# STM32MP13xx register map
File version: 1.5
CPU: CA7 r0p0, little endian, MPU, FPU, 4 interrupt priority bits
Registers are 32-bit, read-write, reset 0x0 unless marked. A register's access mark holds for its fields unless they carry their own. Offsets are from the block's base; [hi:lo] are bit positions; lines under a group give offsets from that group; {n}, {i} and the like mark numbered series; 'fields as' and 'values as' point back to an identical list.

## DFSDM
Base 0x4400D000
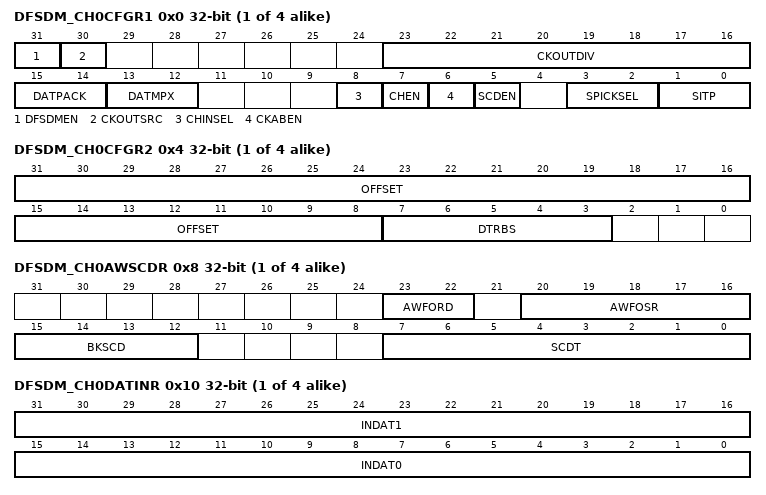
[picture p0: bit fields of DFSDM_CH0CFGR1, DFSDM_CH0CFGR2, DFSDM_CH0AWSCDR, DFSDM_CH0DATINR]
{0x0+0x20*i} DFSDM_CH{i}CFGR1 (i=0..3) — DFSDM channel {i} configuration register
  [31] DFSDMEN — Global enable for DFSDM interface If DFSDM interface is enabled, then it is started to operate according to enabled y channels and enabled x filters settings (CHEN bit in DFSDM_CHyCFGR1 and DFEN bit in DFSDM_FLTxCR1). Data cleared by setting DFSDMEN=0: all registers DFSDM_FLTxISR are set to reset state (x = 0..1) all registers DFSDM_FLTxAWSR are set to reset state (x = 0..1) Note: DFSDMEN is present only in DFSDM_CH0CFGR1 register (channel y=0)
    0=DFSDM interface disabled; 1=DFSDM interface enabled
  [30] CKOUTSRC — Output serial clock source selection This value can be modified only when DFSDMEN=0 (in DFSDM_CH0CFGR1 register). Note: CKOUTSRC is present only in DFSDM_CH0CFGR1 register (channel y=0)
    0=Source for output clock is from system clock; 1=Source for output clock is from audio clock
  [23:16] CKOUTDIV — Output serial clock divider Â 256 (Divider = CKOUTDIV+1). CKOUTDIV also defines the threshold for a clock absence detection. This value can only be modified when DFSDMEN=0 (in DFSDM_CH0CFGR1 register). If DFSDMEN=0 (in DFSDM_CH0CFGR1 register) then CKOUT signal is set to low state (setting is performed one DFSDM clock cycle after DFSDMEN=0). Note: CKOUTDIV is present only in DFSDM_CH0CFGR1 register (channel y=0) 1- 255: Defines the division of system clock for the serial clock output for CKOUT signal in range 2Â -
    0=Output clock generation is disabled (CKOUT signal is set to low state)
  [15:14] DATPACK — Data packing mode in DFSDM_CHyDATINR register. first sample in INDAT0[15:0] (assigned to channel y) second sample INDAT1[15:0] (assigned to channel y) To empty DFSDM_CHyDATINR register, two samples must be read by the digital filter from channel y (INDAT0[15:0] part is read as first sample and then INDAT1[15:0] part is read as next sample). 2: Dual: input data in DFSDM_CHyDATINR register are stored as two samples: first sample INDAT0[15:0] (assigned to channel y) second sample INDAT1[15:0] (assigned to channel y+1) To empty DFSDM_CHyDATINR register first sample must be read by the digital filter from channel y and second sample must be read by another digital filter from channel y+1. Dual mode is available only on even channel numbers (y = 0, 2), for odd channel numbers (y = 1, 3) DFSDM_CHyDATINR is write protected. If an even channel is set to dual mode then the following odd channel must be set into standard mode (DATPACK[1:0]=0) for correct cooperation with even channel. 3: Reserved This value can be modified only when CHEN=0 (in DFSDM_CHyCFGR1 register).
    0=Standard: input data in DFSDM_CHyDATINR register are stored only in INDAT0[15:0]. To empty DFSDM_CHyDATINR register one sample must be read by the DFSDM filter from channel y.; 1=Interleaved: input data in DFSDM_CHyDATINR register are stored as two samples:
  [13:12] DATMPX — Input data multiplexer for channel y 2: Data to channel y are taken from internal DFSDM_CHyDATINR register by direct CPU/DMA write. There can be written one or two 16-bit data samples according DATPACK[1:0] bit field setting. 3: Reserved This value can be modified only when CHEN=0 (in DFSDM_CHyCFGR1 register).
    0=Data to channel y are taken from external serial inputs as 1-bit values. DFSDM_CHyDATINR register is write protected.; 1=Data to channel y are taken from internal analog to digital converter ADCy+1 output register update as 16-bit values (if ADCy+1 is available). Data from ADCs are written into INDAT0[15:0] part of DFSDM_CHyDATINR register.
  [8] CHINSEL — Channel inputs selection This value can be modified only when CHEN=0 (in DFSDM_CHyCFGR1 register).
    0=Channel inputs are taken from pins of the same channel y; 1=Channel inputs are taken from pins of the following channel (channel (y+1) modulo 8)
  [7] CHEN — Channel y enable If channel y is enabled, then serial data receiving is started according to the given channel setting.
    0=Channel y disabled; 1=Channel y enabled
  [6] CKABEN — Clock absence detector enable on channel y
    0=Clock absence detector disabled on channel y; 1=Clock absence detector enabled on channel y
  [5] SCDEN — Short-circuit detector enable on channel y
    0=Input channel y will not be guarded by the short-circuit detector; 1=Input channel y will be continuously guarded by the short-circuit detector
  [3:2] SPICKSEL — SPI clock select for channel y 2: clock coming from internal CKOUT - sampling point on each second CKOUT falling edge. For connection to external Î£â modulator which divides its clock input (from CKOUT) by 2 to generate its output serial communication clock (and this output clock change is active on each clock input rising edge). 3: clock coming from internal CKOUT output - sampling point on each second CKOUT rising edge. For connection to external Î£â modulator which divides its clock input (from CKOUT) by 2 to generate its output serial communication clock (and this output clock change is active on each clock input falling edge). This value can be modified only when CHEN=0 (in DFSDM_CHyCFGR1 register).
    0=clock coming from external CKINy input - sampling point according SITP[1:0]; 1=clock coming from internal CKOUT output - sampling point according SITP[1:0]
  [1:0] SITP — Serial interface type for channel y This value can only be modified when CHEN=0 (in DFSDM_CHyCFGR1 register).
    0=SPI with rising edge to strobe data; 1=SPI with falling edge to strobe data; 2=Manchester coded input on DATINy pin: rising edge = logic 0, falling edge = logic 1; 3=Manchester coded input on DATINy pin: rising edge = logic 1, falling edge = logic 0
{0x4+0x20*i} DFSDM_CH{i}CFGR2 (i=0..3) — DFSDM channel {i} configuration register
  [31:8] OFFSET — 24-bit calibration offset for channel y For channel y, OFFSET is applied to the results of each conversion from this channel. This value is set by software.
  [7:3] DTRBS — Data right bit-shift for channel y will be performed to have final results. Bit-shift is performed before offset correction. The data shift is rounding the result to nearest integer value. The sign of shifted result is maintained (to have valid 24-bit signed format of result data). This value can be modified only when CHEN=0 (in DFSDM_CHyCFGR1 register). 0-31: Defines the shift of the data result coming from the integrator - how many bit shifts to the right
{0x8+0x20*i} DFSDM_CH{i}AWSCDR (i=0..3) — DFSDM channel {i} analog watchdog and short-circuit detector register
  [23:22] AWFORD — Analog watchdog Sinc filter order on channel y 2: Sinc2 filter type 3: Sinc3 filter type Sincx filter type transfer function: FastSinc filter type transfer function: This bit can be modified only when CHEN=0 (in DFSDM_CHyCFGR1 register).
    0=FastSinc filter type; 1=Sinc1 filter type
  [20:16] AWFOSR — Analog watchdog filter oversampling ratio (decimation rate) on channel y also the decimation ratio of the analog data rate. This bit can be modified only when CHEN=0 (in DFSDM_CHyCFGR1 register). Note: If AWFOSR = 0 then the filter has no effect (filter bypass). 0 - 31: Defines the length of the Sinc type filter in the range 1 - 32 (AWFOSR + 1). This number is
  [15:12] BKSCD — Break signal assignment for short-circuit detector on channel y BKSCD[i] = 0: Break i signal not assigned to short-circuit detector on channel y BKSCD[i] = 1: Break i signal assigned to short-circuit detector on channel y
  [7:0] SCDT — short-circuit detector threshold for channel y These bits are written by software to define the threshold counter for the short-circuit detector. If this value is reached, then a short-circuit detector event occurs on a given channel.
{0xC+0x20*i} DFSDM_CH{i}WDATR ro (i=0..3) — DFSDM channel {i} watchdog filter data register
  [15:0] WDATA — Input channel y watchdog data Data converted by the analog watchdog filter for input channel y. This data is continuously converted (no trigger) for this channel, with a limited resolution (OSR=1..32/sinc order = 1..3).
{0x10+0x20*i} DFSDM_CH{i}DATINR (i=0..3) — DFSDM channel {i} data input register
  [31:16] INDAT1 — Input data for channel y or channel y+1 Input parallel channel data to be processed by the digital filter if DATMPX[1:0]=1 or DATMPX[1:0]=2. Data can be written by CPU/DMA (if DATMPX[1:0]=2) or directly by internal ADC (if DATMPX[1:0]=1). If DATPACK[1:0]=0 (standard mode) INDAT0[15:0] is write protected (not used for input sample). If DATPACK[1:0]=1 (interleaved mode) Second channel y data sample is stored into INDAT1[15:0]. First channel y data sample is stored into INDAT0[15:0]. Both samples are read sequentially by DFSDM_FLTx filter as two channel y data samples. If DATPACK[1:0]=2 (dual mode). For even y channels: sample in INDAT1[15:0] is automatically copied into INDAT0[15:0] of channel (y+1). For odd y channels: INDAT1[15:0] is write protected. See for more details. INDAT0[15:1] is in the16-bit signed format.
  [15:0] INDAT0 — Input data for channel y Input parallel channel data to be processed by the digital filter if DATMPX[1:0]=1 or DATMPX[1:0]=2. Data can be written by CPU/DMA (if DATMPX[1:0]=2) or directly by internal ADC (if DATMPX[1:0]=1). If DATPACK[1:0]=0 (standard mode) Channel y data sample is stored into INDAT0[15:0]. If DATPACK[1:0]=1 (interleaved mode) First channel y data sample is stored into INDAT0[15:0]. Second channel y data sample is stored into INDAT1[15:0]. Both samples are read sequentially by DFSDM_FLTx filter as two channel y data samples. If DATPACK[1:0]=2 (dual mode). For even y channels: Channel y data sample is stored into INDAT0[15:0]. For odd y channels: INDAT0[15:0] is write protected. See for more details. INDAT0[15:0] is in the16-bit signed format.
{0x14+0x20*i} DFSDM_CH{i}DLYR (i=0..7)
  [5:0] PLSSKP — Pulses to skip for input data skipping function immediately after writing to this field. Reading of PLSSKP[5:0] returns current value of pulses which will be skipped. If PLSSKP[5:0]=0 then all required data samples were already skipped. Note: User can update PLSSKP[5:0] also when PLSSKP[5:0] is not zero. 0-63: Defines the number of serial input samples that will be skipped. Skipping is applied
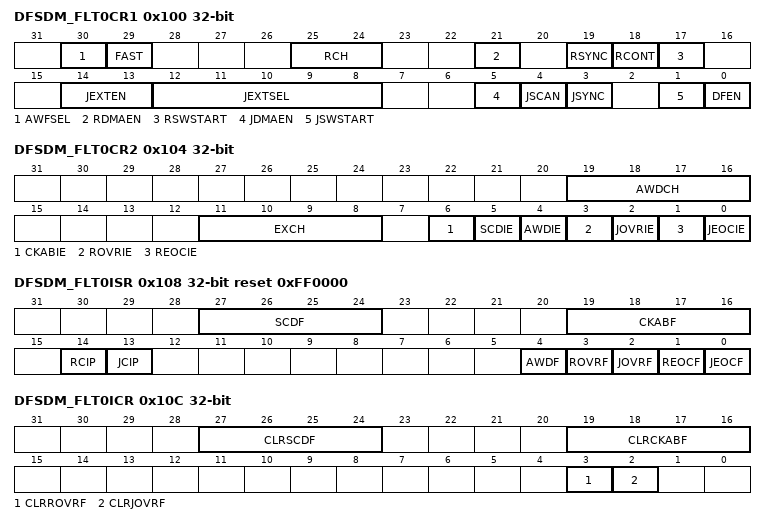
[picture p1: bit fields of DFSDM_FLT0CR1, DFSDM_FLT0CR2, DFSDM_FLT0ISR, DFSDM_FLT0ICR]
0x100 DFSDM_FLT0CR1
  [30] AWFSEL — Analog watchdog fast mode select
    0=Analog watchdog on data output value (after the digital filter). The comparison is done after offset correction and shift; 1=Analog watchdog on channel transceivers value (after watchdog filter)
  [29] FAST — Fast conversion mode selection for regular conversions When converting a regular conversion in continuous mode, having enabled the fast mode causes each conversion (except the first) to execute faster than in standard mode. This bit has no effect on conversions which are not continuous. This bit can be modified only when DFEN=0 (DFSDM_FLTxCR1). if FAST=0 (or first conversion in continuous mode if FAST=1): t = [FOSR * (IOSR-1 + FORD) + FORD] / fCKIN ..... for Sincx filters t = [FOSR * (IOSR-1 + 4) + 2] / fCKIN ..... for FastSinc filter if FAST=1 in continuous mode (except first conversion): t = [FOSR * IOSR] / fCKIN in case if FOSR = FOSR[9:0]+1 = 1 (filter bypassed, active only integrator): t = IOSR / fCKIN (... but CNVCNT=0) where: fCKIN is the channel input clock frequency (on given channel CKINy pin) or input data rate in case of parallel data input.
    0=Fast conversion mode disabled; 1=Fast conversion mode enabled
  [25:24] RCH — Regular channel selection ... 3: Chanel 3 is selected as the regular channel Writing this bit when RCIP=1 takes effect when the next regular conversion begins. This is especially useful in continuous mode (when RCONT=1). It also affects regular conversions which are pending (due to ongoing injected conversion).
    0=Channel 0 is selected as the regular channel; 1=Channel 1 is selected as the regular channel
  [21] RDMAEN — DMA channel enabled to read data for the regular conversion This bit can be modified only when DFEN=0 (DFSDM_FLTxCR1).
    0=The DMA channel is not enabled to read regular data; 1=The DMA channel is enabled to read regular data
  [19] RSYNC — Launch regular conversion synchronously with DFSDM_FLT0 This bit can be modified only when DFEN=0 (DFSDM_FLTxCR1).
    0=Do not launch a regular conversion synchronously with DFSDM_FLT0; 1=Launch a regular conversion in this DFSDM_FLTx at the very moment when a regular conversion is launched in DFSDM_FLT0
  [18] RCONT — Continuous mode selection for regular conversions Writing '0â to this bit while a continuous regular conversion is already in progress stops the continuous mode immediately.
    0=The regular channel is converted just once for each conversion request; 1=The regular channel is converted repeatedly after each conversion request
  [17] RSWSTART — Software start of a conversion on the regular channel This bit is always read as '0â.
    0=Writing '0â has no effect; 1=Writing '1â makes a request to start a conversion on the regular channel and causes RCIP to become '1â. If RCIP=1 already, writing to RSWSTART has no effect. Writing '1â has no effect if RSYNC=1.
  [14:13] JEXTEN — Trigger enable and trigger edge selection for injected conversions This bit can be modified only when DFEN=0 (DFSDM_FLTxCR1).
    0=Trigger detection is disabled; 1=Each rising edge on the selected trigger makes a request to launch an injected conversion; 2=Each falling edge on the selected trigger makes a request to launch an injected conversion; 3=Both rising edges and falling edges on the selected trigger make requests to launch injected conversions
  [12:8] JEXTSEL — Trigger signal selection for launching injected conversions This bit can be modified only when DFEN=0 (DFSDM_FLTxCR1). Note: synchronous trigger has latency up to one fDFSDMCLK clock cycle (with deterministic jitter), asynchronous trigger has latency 2-3 fDFSDMCLK clock cycles (with jitter up to 1 cycle). DFSDM_FLTx 0x00 dfsdm_jtrg0 0x01 dfsdm_jtrg1 ... 0x1E dfsdm_jtrg30 0x1F dfsdm_jtrg31 Refer to . 0x0-0x1F: Trigger inputs selected by the following table (internal or external trigger).
  [5] JDMAEN — DMA channel enabled to read data for the injected channel group This bit can be modified only when DFEN=0 (DFSDM_FLTxCR1).
    0=The DMA channel is not enabled to read injected data; 1=The DMA channel is enabled to read injected data
  [4] JSCAN — Scanning conversion mode for injected conversions This bit can be modified only when DFEN=0 (DFSDM_FLTxCR1). Writing JCHG if JSCAN=0 resets the channel selection to the lowest selected channel.
    0=One channel conversion is performed from the injected channel group and next the selected channel from this group is selected; 1=The series of conversions for the injected group channels is executed, starting over with the lowest selected channel
  [3] JSYNC — Launch an injected conversion synchronously with the DFSDM_FLT0 JSWSTART trigger This bit can be modified only when DFEN=0 (DFSDM_FLTxCR1).
    0=Do not launch an injected conversion synchronously with DFSDM_FLT0; 1=Launch an injected conversion in this DFSDM_FLTx at the very moment when an injected conversion is launched in DFSDM_FLT0 by its JSWSTART trigger
  [1] JSWSTART — Start a conversion of the injected group of channels This bit is always read as '0â.
    0=Writing '0â has no effect; 1=Writing '1â makes a request to convert the channels in the injected conversion group, causing JCIP to become '1â at the same time. If JCIP=1 already, then writing to JSWSTART has no effect. Writing '1â has no effect if JSYNC=1.
  [0] DFEN — DFSDM_FLTx enable Data which are cleared by setting DFEN=0: register DFSDM_FLTxISR is set to the reset state register DFSDM_FLTxAWSR is set to the reset state
    0=DFSDM_FLTx is disabled. All conversions of given DFSDM_FLTx are stopped immediately and all DFSDM_FLTx functions are stopped.; 1=DFSDM_FLTx is enabled. If DFSDM_FLTx is enabled, then DFSDM_FLTx starts operating according to its setting.
0x104 DFSDM_FLT0CR2
  [19:16] AWDCH — Analog watchdog channel selection These bits select the input channel to be guarded continuously by the analog watchdog. AWDCH[y] = 0: Analog watchdog is disabled on channel y AWDCH[y] = 1: Analog watchdog is enabled on channel y
  [11:8] EXCH — Extremes detector channel selection These bits select the input channels to be taken by the Extremes detector. EXCH[y] = 0: Extremes detector does not accept data from channel y EXCH[y] = 1: Extremes detector accepts data from channel y
  [6] CKABIE — Clock absence interrupt enable Please see the explanation of CKABF[3:0] in DFSDM_FLTxISR. Note: CKABIE is present only in DFSDM_FLT0CR2 register (filter x=0)
    0=Detection of channel input clock absence interrupt is disabled; 1=Detection of channel input clock absence interrupt is enabled
  [5] SCDIE — Short-circuit detector interrupt enable Please see the explanation of SCDF[3:0] in DFSDM_FLTxISR. Note: SCDIE is present only in DFSDM_FLT0CR2 register (filter x=0)
    0=short-circuit detector interrupt is disabled; 1=short-circuit detector interrupt is enabled
  [4] AWDIE — Analog watchdog interrupt enable Please see the explanation of AWDF in DFSDM_FLTxISR.
    0=Analog watchdog interrupt is disabled; 1=Analog watchdog interrupt is enabled
  [3] ROVRIE — Regular data overrun interrupt enable Please see the explanation of ROVRF in DFSDM_FLTxISR.
    0=Regular data overrun interrupt is disabled; 1=Regular data overrun interrupt is enabled
  [2] JOVRIE — Injected data overrun interrupt enable Please see the explanation of JOVRF in DFSDM_FLTxISR.
    0=Injected data overrun interrupt is disabled; 1=Injected data overrun interrupt is enabled
  [1] REOCIE — Regular end of conversion interrupt enable Please see the explanation of REOCF in DFSDM_FLTxISR.
    0=Regular end of conversion interrupt is disabled; 1=Regular end of conversion interrupt is enabled
  [0] JEOCIE — Injected end of conversion interrupt enable Please see the explanation of JEOCF in DFSDM_FLTxISR.
    0=Injected end of conversion interrupt is disabled; 1=Injected end of conversion interrupt is enabled
0x108 DFSDM_FLT0ISR ro reset 0xFF0000
  [27:24] SCDF — short-circuit detector flag SDCF[y]=0: No short-circuit detector event occurred on channel y SDCF[y]=1: The short-circuit detector counter reaches, on channel y, the value programmed in the DFSDM_CHyAWSCDR registers This bit is set by hardware. It can be cleared by software using the corresponding CLRSCDF[y] bit in the DFSDM_FLTxICR register. SCDF[y] is cleared also by hardware when CHEN[y] = 0 (given channel is disabled). Note: SCDF[3:0] is present only in DFSDM_FLT0ISR register (filter x=0)
  [19:16] CKABF — Clock absence flag CKABF[y]=0: Clock signal on channel y is present. CKABF[y]=1: Clock signal on channel y is not present. Given y bit is set by hardware when clock absence is detected on channel y. It is held at CKABF[y]=1 state by hardware when CHEN=0 (see DFSDM_CHyCFGR1 register). It is held at CKABF[y]=1 state by hardware when the transceiver is not yet synchronized.It can be cleared by software using the corresponding CLRCKABF[y] bit in the DFSDM_FLTxICR register. Note: CKABF[3:0] is present only in DFSDM_FLT0ISR register (filter x=0)
  [14] RCIP — Regular conversion in progress status A request to start a regular conversion is ignored when RCIP=1.
    0=No request to convert the regular channel has been issued; 1=The conversion of the regular channel is in progress or a request for a regular conversion is pending
  [13] JCIP — Injected conversion in progress status A request to start an injected conversion is ignored when JCIP=1.
    0=No request to convert the injected channel group (neither by software nor by trigger) has been issued; 1=The conversion of the injected channel group is in progress or a request for a injected conversion is pending, due either to '1â being written to JSWSTART or to a trigger detection
  [4] AWDF — Analog watchdog This bit is set by hardware. It is cleared by software by clearing all source flag bits AWHTF[3:0] and AWLTF[3:0] in DFSDM_FLTxAWSR register (by writing '1â into the clear bits in DFSDM_FLTxAWCFR register).
    0=No Analog watchdog event occurred; 1=The analog watchdog block detected voltage which crosses the value programmed in the DFSDM_FLTxAWLTR or DFSDM_FLTxAWHTR registers
  [3] ROVRF — Regular conversion overrun flag This bit is set by hardware. It can be cleared by software using the CLRROVRF bit in the DFSDM_FLTxICR register.
    0=No regular conversion overrun has occurred; 1=A regular conversion overrun has occurred, which means that a regular conversion finished while REOCF was already '1â. RDATAR is not affected by overruns
  [2] JOVRF — Injected conversion overrun flag This bit is set by hardware. It can be cleared by software using the CLRJOVRF bit in the DFSDM_FLTxICR register.
    0=No injected conversion overrun has occurred; 1=An injected conversion overrun has occurred, which means that an injected conversion finished while JEOCF was already '1â. JDATAR is not affected by overruns
  [1] REOCF — End of regular conversion flag This bit is set by hardware. It is cleared when the software or DMA reads DFSDM_FLTxRDATAR.
    0=No regular conversion has completed; 1=A regular conversion has completed and its data may be read
  [0] JEOCF — End of injected conversion flag This bit is set by hardware. It is cleared when the software or DMA reads DFSDM_FLTxJDATAR.
    0=No injected conversion has completed; 1=An injected conversion has completed and its data may be read
0x10C DFSDM_FLT0ICR
  [27:24] CLRSCDF — Clear the short-circuit detector flag CLRSCDF[y]=0: Writing '0â has no effect CLRSCDF[y]=1: Writing '1â to position y clears the corresponding SCDF[y] bit in the DFSDM_FLTxISR register Note: CLRSCDF[3:0] is present only in DFSDM_FLT0ICR register (filter x=0)
  [19:16] CLRCKABF — Clear the clock absence flag CLRCKABF[y]=0: Writing '0â has no effect CLRCKABF[y]=1: Writing '1â to position y clears the corresponding CKABF[y] bit in the DFSDM_FLTxISR register. When the transceiver is not yet synchronized, the clock absence flag is set and cannot be cleared by CLRCKABF[y]. Note: CLRCKABF[3:0] is present only in DFSDM_FLT0ICR register (filter x=0)
  [3] CLRROVRF — Clear the regular conversion overrun flag
    0=Writing '0â has no effect; 1=Writing '1â clears the ROVRF bit in the DFSDM_FLTxISR register
  [2] CLRJOVRF — Clear the injected conversion overrun flag
    0=Writing '0â has no effect; 1=Writing '1â clears the JOVRF bit in the DFSDM_FLTxISR register
0x110 DFSDM_FLT0JCHGR reset 0x1
  [3:0] JCHG — Injected channel group selection JCHG[y]=0: channel y is not part of the injected group JCHG[y]=1: channel y is part of the injected group If JSCAN=1, each of the selected channels is converted, one after another. The lowest channel (channel 0, if selected) is converted first and the sequence ends at the highest selected channel. If JSCAN=0, then only one channel is converted from the selected channels, and the channel selection is moved to the next channel. Writing JCHG, if JSCAN=0, resets the channel selection to the lowest selected channel. At least one channel must always be selected for the injected group. Writes causing all JCHG bits to be zero are ignored.
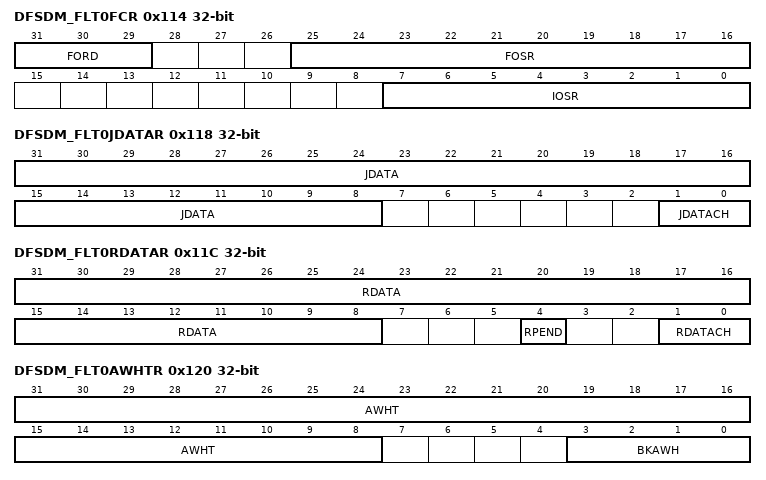
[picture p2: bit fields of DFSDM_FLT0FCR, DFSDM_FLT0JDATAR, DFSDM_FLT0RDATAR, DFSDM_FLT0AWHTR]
0x114 DFSDM_FLT0FCR
  [31:29] FORD — Sinc filter order 2: Sinc2 filter type 3: Sinc3 filter type 4: Sinc4 filter type 5: Sinc5 filter type 6-7: Reserved Sincx filter type transfer function: FastSinc filter type transfer function: This bit can only be modified when DFEN=0 (DFSDM_FLTxCR1).
    0=FastSinc filter type; 1=Sinc1 filter type
  [25:16] FOSR — Sinc filter oversampling ratio (decimation rate) number is also the decimation ratio of the output data rate from filter. This bit can only be modified when DFEN=0 (DFSDM_FLTxCR1) Note: If FOSR = 0, then the filter has no effect (filter bypass). 0 - 1023: Defines the length of the Sinc type filter in the range 1 - 1024 (FOSR = FOSR[9:0] +1). This
  [7:0] IOSR — Integrator oversampling ratio (averaging length) from Sinc filter will be summed into one output data sample from the integrator. The output data rate from the integrator will be decreased by this number (additional data decimation ratio). This bit can only be modified when DFEN=0 (DFSDM_FLTxCR1) Note: If IOSR = 0, then the Integrator has no effect (Integrator bypass). 0- 255: The length of the Integrator in the range 1 - 256 (IOSR + 1). Defines how many samples
0x118 DFSDM_FLT0JDATAR ro
  [31:8] JDATA — Injected group conversion data When each conversion of a channel in the injected group finishes, its resulting data is stored in this field. The data is valid when JEOCF=1. Reading this register clears the corresponding JEOCF.
  [1:0] JDATACH — Injected channel most recently converted When each conversion of a channel in the injected group finishes, JDATACH[1:0] is updated to indicate which channel was converted. Thus, JDATA[23:0] holds the data that corresponds to the channel indicated by JDATACH[1:0].
0x11C DFSDM_FLT0RDATAR ro
  [31:8] RDATA — Regular channel conversion data When each regular conversion finishes, its data is stored in this register. The data is valid when REOCF=1. Reading this register clears the corresponding REOCF.
  [4] RPEND — Regular channel pending data Regular data in RDATA[23:0] was delayed due to an injected channel trigger during the conversion
  [1:0] RDATACH — Regular channel most recently converted When each regular conversion finishes, RDATACH[1:0] is updated to indicate which channel was converted (because regular channel selection RCH[1:0] in DFSDM_FLTxCR1 register can be updated during regular conversion). Thus RDATA[23:0] holds the data that corresponds to the channel indicated by RDATACH[1:0].
0x120 DFSDM_FLT0AWHTR
  [31:8] AWHT — Analog watchdog high threshold These bits are written by software to define the high threshold for the analog watchdog. Note: In case channel transceivers monitor (AWFSEL=1), the higher 16 bits (AWHT[23:8]) define the 16-bit threshold as compared with the analog watchdog filter output (because data coming from the analog watchdog filter are up to a 16-bit resolution). Bits AWHT[7:0] are not taken into comparison in this case.
  [3:0] BKAWH — Break signal assignment to analog watchdog high threshold event BKAWH[i] = 0: Break i signal is not assigned to an analog watchdog high threshold event BKAWH[i] = 1: Break i signal is assigned to an analog watchdog high threshold event
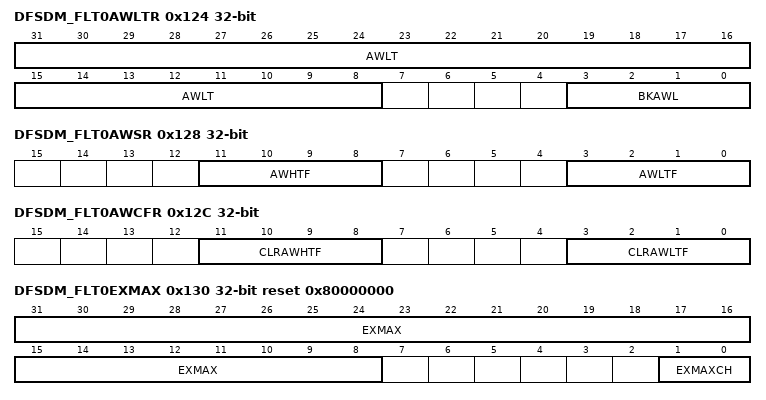
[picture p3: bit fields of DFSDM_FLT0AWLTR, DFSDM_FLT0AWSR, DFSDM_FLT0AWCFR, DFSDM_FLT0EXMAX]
0x124 DFSDM_FLT0AWLTR
  [31:8] AWLT — Analog watchdog low threshold These bits are written by software to define the low threshold for the analog watchdog. Note: In case channel transceivers monitor (AWFSEL=1), only the higher 16 bits (AWLT[23:8]) define the 16-bit threshold as compared with the analog watchdog filter output (because data coming from the analog watchdog filter are up to a 16-bit resolution). Bits AWLT[7:0] are not taken into comparison in this case.
  [3:0] BKAWL — Break signal assignment to analog watchdog low threshold event BKAWL[i] = 0: Break i signal is not assigned to an analog watchdog low threshold event BKAWL[i] = 1: Break i signal is assigned to an analog watchdog low threshold event
0x128 DFSDM_FLT0AWSR ro
  [11:8] AWHTF — Analog watchdog high threshold flag AWHTF[y]=1 indicates a high threshold error on channel y. It is set by hardware. It can be cleared by software using the corresponding CLRAWHTF[y] bit in the DFSDM_FLTxAWCFR register.
  [3:0] AWLTF — Analog watchdog low threshold flag AWLTF[y]=1 indicates a low threshold error on channel y. It is set by hardware. It can be cleared by software using the corresponding CLRAWLTF[y] bit in the DFSDM_FLTxAWCFR register.
0x12C DFSDM_FLT0AWCFR
  [11:8] CLRAWHTF — Clear the analog watchdog high threshold flag CLRAWHTF[y]=0: Writing '0â has no effect CLRAWHTF[y]=1: Writing '1â to position y clears the corresponding AWHTF[y] bit in the DFSDM_FLTxAWSR register
  [3:0] CLRAWLTF — Clear the analog watchdog low threshold flag CLRAWLTF[y]=0: Writing '0â has no effect CLRAWLTF[y]=1: Writing '1â to position y clears the corresponding AWLTF[y] bit in the DFSDM_FLTxAWSR register
0x130 DFSDM_FLT0EXMAX ro reset 0x80000000
  [31:8] EXMAX read-sets — Extremes detector maximum value These bits are set by hardware and indicate the highest value converted by DFSDM_FLTx. EXMAX[23:0] bits are reset to value (0x800000) by reading of this register.
  [1:0] EXMAXCH — Extremes detector maximum data channel. These bits contains information about the channel on which the data is stored into EXMAX[23:0]. Bits are cleared by reading of this register.
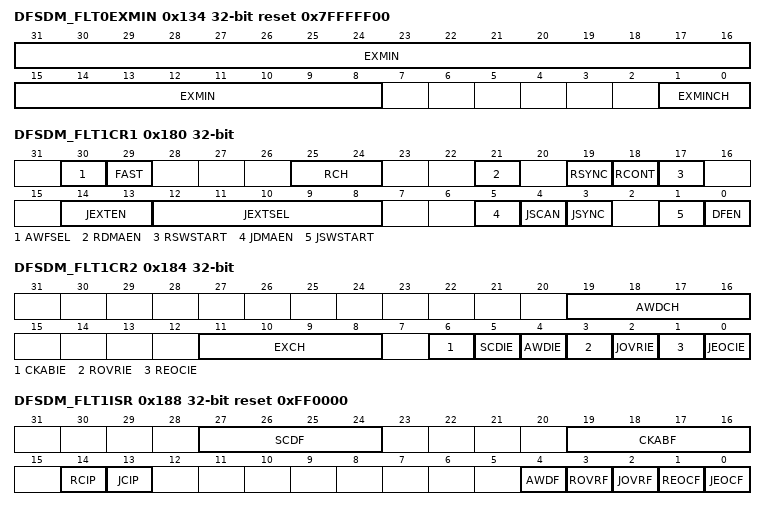
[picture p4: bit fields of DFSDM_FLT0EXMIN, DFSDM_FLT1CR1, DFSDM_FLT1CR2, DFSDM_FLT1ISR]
0x134 DFSDM_FLT0EXMIN access per field reset 0x7FFFFF00
  [31:8] EXMIN rw read-clears — Extremes detector minimum value These bits are set by hardware and indicate the lowest value converted by DFSDM_FLTx. EXMIN[23:0] bits are reset to value (0x7FFFFF) by reading of this register.
  [1:0] EXMINCH ro — Extremes detector minimum data channel These bits contain information about the channel on which the data is stored into EXMIN[23:0]. Bits are cleared by reading of this register.
0x138 DFSDM_FLT0CNVTIMR ro
  [31:4] CNVCNT — 28-bit timer counting conversion time t = CNVCNT[27:0] / fDFSDMCLK The timer has an input clock from DFSDM clock (system clock fDFSDMCLK). Conversion time measurement is started on each conversion start and stopped when conversion finishes (interval between first and last serial sample). Only in case of filter bypass (FOSR[9:0] = 0) is the conversion time measurement stopped and CNVCNT[27:0] = 0. The counted time is: if FAST=0 (or first conversion in continuous mode if FAST=1): t = [FOSR * (IOSR-1 + FORD) + FORD] / fCKIN ..... for Sincx filters t = [FOSR * (IOSR-1 + 4) + 2] / fCKIN ..... for FastSinc filter if FAST=1 in continuous mode (except first conversion): t = [FOSR * IOSR] / fCKIN in case if FOSR = FOSR[9:0]+1 = 1 (filter bypassed, active only integrator): CNVCNT = 0 (counting is stopped, conversion time: t = IOSR / fCKIN) where: fCKIN is the channel input clock frequency (on given channel CKINy pin) or input data rate in case of parallel data input (from internal ADC or from CPU/DMA write) Note: When conversion is interrupted (e.g. by disable/enable selected channel) the timer counts also this interruption time.
0x180 DFSDM_FLT1CR1
  fields as DFSDM_FLT0CR1
0x184 DFSDM_FLT1CR2
  fields as DFSDM_FLT0CR2
0x188 DFSDM_FLT1ISR ro reset 0xFF0000
  fields as DFSDM_FLT0ISR
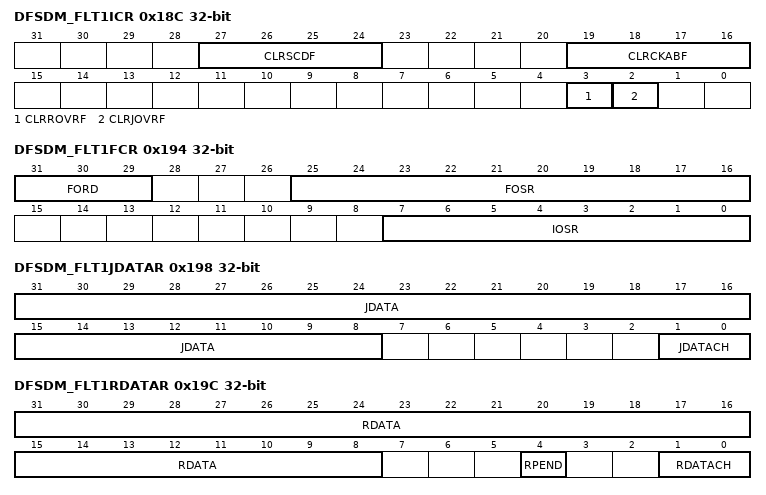
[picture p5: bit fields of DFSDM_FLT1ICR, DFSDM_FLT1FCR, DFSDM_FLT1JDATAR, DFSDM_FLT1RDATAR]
0x18C DFSDM_FLT1ICR
  fields as DFSDM_FLT0ICR
0x190 DFSDM_FLT1JCHGR reset 0x1
  fields as DFSDM_FLT0JCHGR
0x194 DFSDM_FLT1FCR
  fields as DFSDM_FLT0FCR
0x198 DFSDM_FLT1JDATAR ro
  fields as DFSDM_FLT0JDATAR
0x19C DFSDM_FLT1RDATAR ro
  fields as DFSDM_FLT0RDATAR
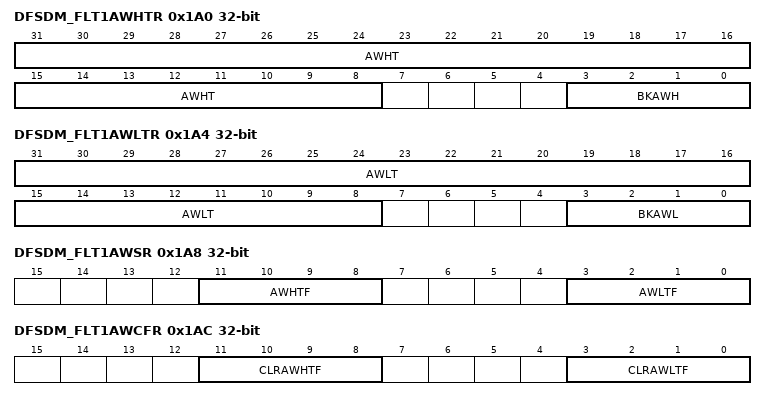
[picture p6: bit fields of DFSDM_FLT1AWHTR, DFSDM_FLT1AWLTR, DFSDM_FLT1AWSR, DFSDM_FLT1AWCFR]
0x1A0 DFSDM_FLT1AWHTR
  fields as DFSDM_FLT0AWHTR
0x1A4 DFSDM_FLT1AWLTR
  fields as DFSDM_FLT0AWLTR
0x1A8 DFSDM_FLT1AWSR ro
  fields as DFSDM_FLT0AWSR
0x1AC DFSDM_FLT1AWCFR
  fields as DFSDM_FLT0AWCFR
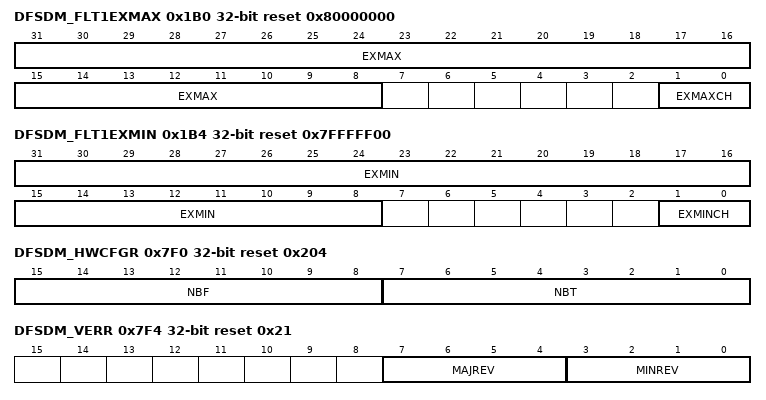
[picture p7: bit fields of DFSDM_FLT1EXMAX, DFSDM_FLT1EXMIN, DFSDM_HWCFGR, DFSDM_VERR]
0x1B0 DFSDM_FLT1EXMAX ro reset 0x80000000
  fields as DFSDM_FLT0EXMAX
0x1B4 DFSDM_FLT1EXMIN access per field reset 0x7FFFFF00
  fields as DFSDM_FLT0EXMIN
0x1B8 DFSDM_FLT1CNVTIMR ro
  fields as DFSDM_FLT0CNVTIMR
0x7F0 DFSDM_HWCFGR ro reset 0x204 — DFSDM hardware configuration register
  [15:8] NBF — Number of implemented filters Defines how many filters are implemented in DFSDM peripheral.
  [7:0] NBT — Number of implemented transceivers Defines how many transceivers (input channels) are implemented in DFSDM peripheral.
0x7F4 DFSDM_VERR ro reset 0x21 — DFSDM version register
  [7:4] MAJREV — Major revision of the DFSDM peripheral These bits return the DFSDM major revision (in range 0..15).
  [3:0] MINREV — Minor revision of the DFSDM peripheral These bits return the DFSDM minor revision (in range 0..15).
0x7F8 DFSDM_IPIDR ro reset 0x110031 — DFSDM identification register
  [31:0] ID — Peripheral identifier Bits [31:0]: these bits returns the DFSDM identifier ID[31:0] = 0x0011 0031
0x7FC DFSDM_SIDR ro reset 0xA3C5DD02 — DFSDM size identification register
  [31:0] SID — Size identification of DFSDM peripheral Bits [31:8]: fixed code = 0xA3C5DD Bits [7:0]: these bits returns the size of the memory region allocated to DFSDM registers.
    2=2KB allocated by DFSDM peripheral (fixed value)
